# LPC54S018M register map
Vendor: nxp.com; File version: 1.0
CPU: CM4 r0p1, little endian, MPU, FPU, VTOR, 3 interrupt priority bits
Registers are 32-bit, read-write, reset 0x0 unless marked. A register's access mark holds for its fields unless they carry their own. Offsets are from the block's base; [hi:lo] are bit positions; {n}, {i} and the like mark numbered series; 'fields as' and 'values as' point back to an identical list.

## LCD — LPC54S60x/LPC5460x LCD controller
Base 0x40083000
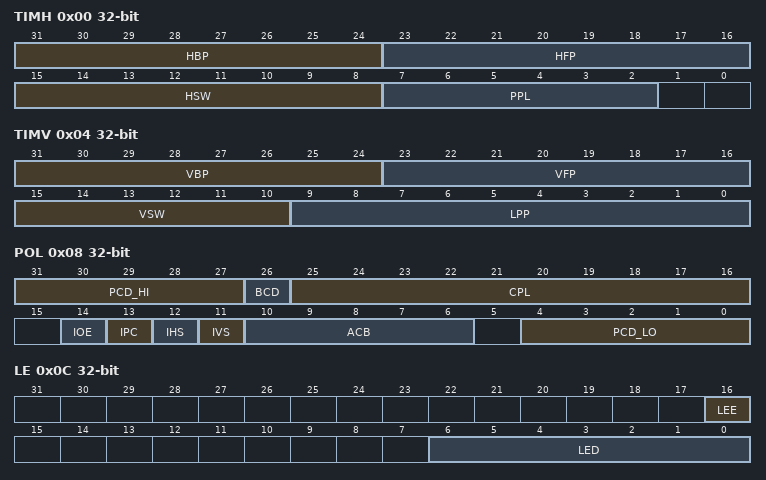
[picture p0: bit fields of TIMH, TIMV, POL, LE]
0x00 TIMH — Horizontal Timing Control register
  [31:24] HBP — Horizontal back porch.
  [23:16] HFP — Horizontal front porch.
  [15:8] HSW — Horizontal synchronization pulse width.
  [7:2] PPL — Pixels-per-line.
0x04 TIMV — Vertical Timing Control register
  [31:24] VBP — Vertical back porch.
  [23:16] VFP — Vertical front porch.
  [15:10] VSW — Vertical synchronization pulse width.
  [9:0] LPP — Lines per panel.
0x08 POL — Clock and Signal Polarity Control register
  [31:27] PCD_HI — Upper five bits of panel clock divisor.
  [26] BCD — Bypass panel clock divider.
  [25:16] CPL — Clocks per line.
  [14] IOE — Invert output enable.
  [13] IPC — Invert panel clock.
  [12] IHS — Invert horizontal synchronization.
  [11] IVS — Invert vertical synchronization.
  [10:6] ACB — AC bias pin frequency.
  [4:0] PCD_LO — Lower five bits of panel clock divisor.
0x0C LE — Line End Control register
  [16] LEE — LCD Line end enable.
  [6:0] LED — Line-end delay.
0x10 UPBASE — Upper Panel Frame Base Address register
  [31:3] LCDUPBASE — LCD upper panel base address.
0x14 LPBASE — Lower Panel Frame Base Address register
  [31:3] LCDLPBASE — LCD lower panel base address.
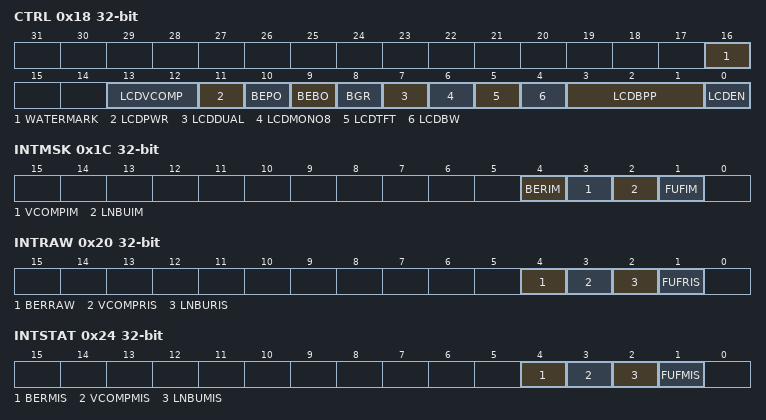
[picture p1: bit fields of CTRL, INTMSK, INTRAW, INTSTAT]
0x18 CTRL — LCD Control register
  [16] WATERMARK — LCD DMA FIFO watermark level.
  [13:12] LCDVCOMP — LCD Vertical Compare Interrupt.
  [11] LCDPWR — LCD power enable.
  [10] BEPO — Big-Endian Pixel Ordering.
  [9] BEBO — Big-endian Byte Order.
  [8] BGR — Color format selection.
  [7] LCDDUAL — Single or Dual LCD panel selection.
  [6] LCDMONO8 — Monochrome LCD interface width.
  [5] LCDTFT — LCD panel TFT type selection.
  [4] LCDBW — STN LCD monochrome/color selection.
  [3:1] LCDBPP — LCD bits per pixel.
  [0] LCDEN — LCD enable control bit.
0x1C INTMSK — Interrupt Mask register
  [4] BERIM — AHB master error interrupt enable.
  [3] VCOMPIM — Vertical compare interrupt enable.
  [2] LNBUIM — LCD next base address update interrupt enable.
  [1] FUFIM — FIFO underflow interrupt enable.
0x20 INTRAW ro — Raw Interrupt Status register
  [4] BERRAW — AHB master bus error raw interrupt status.
  [3] VCOMPRIS — Vertical compare raw interrupt status.
  [2] LNBURIS — LCD next address base update raw interrupt status.
  [1] FUFRIS — FIFO underflow raw interrupt status.
0x24 INTSTAT ro — Masked Interrupt Status register
  [4] BERMIS — AHB master bus error masked interrupt status.
  [3] VCOMPMIS — Vertical compare masked interrupt status.
  [2] LNBUMIS — LCD next address base update masked interrupt status.
  [1] FUFMIS — FIFO underflow masked interrupt status.
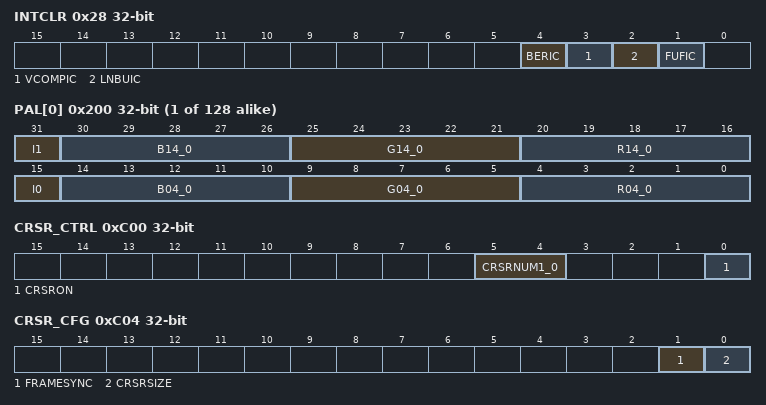
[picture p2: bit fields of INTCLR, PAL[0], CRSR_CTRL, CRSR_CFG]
0x28 INTCLR — Interrupt Clear register
  [4] BERIC wo — AHB master error interrupt clear.
  [3] VCOMPIC wo — Vertical compare interrupt clear.
  [2] LNBUIC wo — LCD next address base update interrupt clear.
  [1] FUFIC wo — FIFO underflow interrupt clear.
0x2C UPCURR ro — Upper Panel Current Address Value register
  [31:0] LCDUPCURR — LCD Upper Panel Current Address.
0x30 LPCURR ro — Lower Panel Current Address Value register
  [31:0] LCDLPCURR — LCD Lower Panel Current Address.
{0x200+4i} PAL[{i}] (i=0..127) — 256x16-bit Color Palette registers
  [31] I1 — Intensity / unused bit.
  [30:26] B14_0 — Blue palette data.
  [25:21] G14_0 — Green palette data.
  [20:16] R14_0 — Red palette data.
  [15] I0 — Intensity / unused bit.
  [14:10] B04_0 — Blue palette data.
  [9:5] G04_0 — Green palette data.
  [4:0] R04_0 — Red palette data.
{0x800+4i} CRSR_IMG[{i}] (i=0..255) — Cursor Image registers
  [31:0] CRSR_IMG — Cursor Image data.
0xC00 CRSR_CTRL — Cursor Control register
  [5:4] CRSRNUM1_0 — Cursor image number.
  [0] CRSRON — Cursor enable.
0xC04 CRSR_CFG — Cursor Configuration register
  [1] FRAMESYNC — Cursor frame synchronization type.
  [0] CRSRSIZE — Cursor size selection.
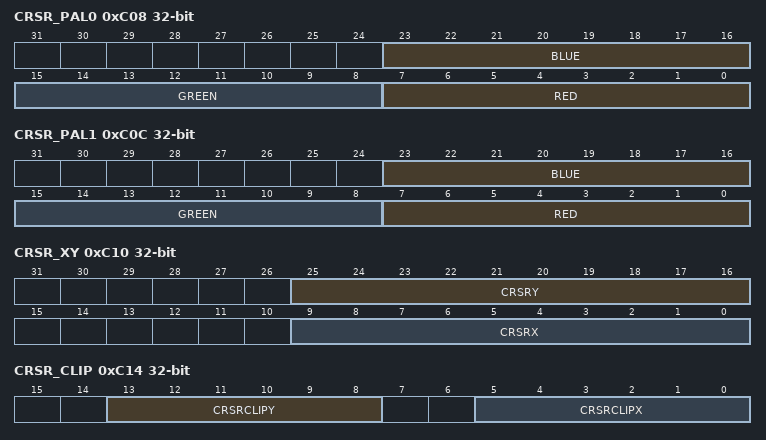
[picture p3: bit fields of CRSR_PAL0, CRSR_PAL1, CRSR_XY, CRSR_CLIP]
0xC08 CRSR_PAL0 — Cursor Palette register 0
  [23:16] BLUE — Blue color component.
  [15:8] GREEN — Green color component.
  [7:0] RED — Red color component.
0xC0C CRSR_PAL1 — Cursor Palette register 1
  fields as CRSR_PAL0
0xC10 CRSR_XY — Cursor XY Position register
  [25:16] CRSRY — Y ordinate of the cursor origin measured in pixels.
  [9:0] CRSRX — X ordinate of the cursor origin measured in pixels.
0xC14 CRSR_CLIP — Cursor Clip Position register
  [13:8] CRSRCLIPY — Cursor clip position for Y direction.
  [5:0] CRSRCLIPX — Cursor clip position for X direction.
0xC20 CRSR_INTMSK — Cursor Interrupt Mask register
  [0] CRSRIM — Cursor interrupt mask.
0xC24 CRSR_INTCLR wo — Cursor Interrupt Clear register
  [0] CRSRIC — Cursor interrupt clear.
0xC28 CRSR_INTRAW ro — Cursor Raw Interrupt Status register
  [0] CRSRRIS — Cursor raw interrupt status.
0xC2C CRSR_INTSTAT ro — Cursor Masked Interrupt Status register
  [0] CRSRMIS — Cursor masked interrupt status.
